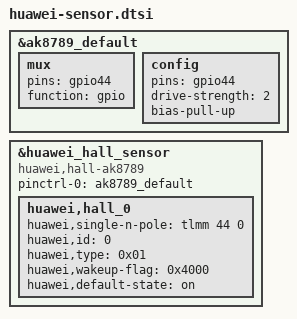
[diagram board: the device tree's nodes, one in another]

&ak8789_default {
	mux {
		pins = "gpio44";
		function =  "gpio";
	};
	config {
		pins = "gpio44";
		drive-strength = <2>;
		bias-pull-up;
	};
};

&huawei_hall_sensor {
	compatible = "huawei,hall-ak8789";
	status = "ok";
	pinctrl-names = "default";
	pinctrl-0 = <&ak8789_default>;

	huawei,hall_0 {
		huawei,single-n-pole = <&tlmm 44 0>;
		huawei,id = <0>;
		huawei,type = <0x01>;
		huawei,wakeup-flag = <0x4000>;
		huawei,default-state = "on";
	};
};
